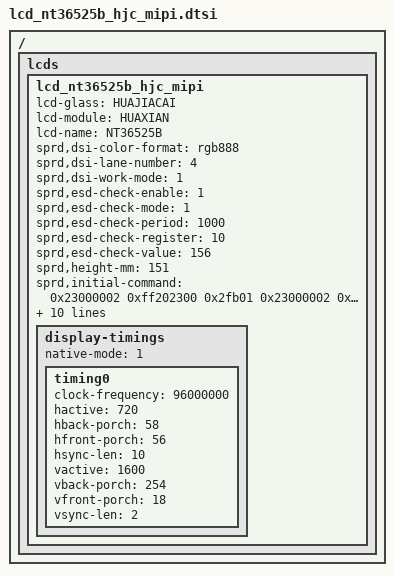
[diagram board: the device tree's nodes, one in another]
/ {
	fragment {
		target-path = "/";
		__overlay__ {
			lcds {
				lcd_nt36525b_hjc_mipi: lcd_nt36525b_hjc_mipi {
					lcd-glass = "HUAJIACAI";
					lcd-module = "HUAXIAN";
					lcd-name = "NT36525B";
					sprd,dsi-color-format = "rgb888";
					sprd,dsi-lane-number = <4>;
					sprd,dsi-work-mode = <1>;
					sprd,esd-check-enable = <1>;
					sprd,esd-check-mode = <1>;
					sprd,esd-check-period = <1000>;
					sprd,esd-check-register = <10>;
					sprd,esd-check-value = <156>;
					sprd,height-mm = <151>;
					sprd,initial-command = <
						0x23000002 0xff202300 0x2fb01 0x23000002 0x3542300 0x205b1 0x23000002 0x76e2300
						0x208cb 0x23000002 0xe872300 0x20f69 0x23000002 0x69a92300 0x28800 0x23000002 0x89582300
						0x28a58 0x23000002 0x8b582300 0x28c58 0x23000002 0x95d72300 0x296d7 0x23000002 0xff232300
						0x2fb01 0x23000002 0x12b42300 0x215e9 0x23000002 0x160b2300 0x2ff24 0x23000002 0xfb012300
						0x20005 0x23000002 0x1002300 0x2021f 0x23000002 0x31e2300 0x20420 0x23000002 0x5002300
						0x20600 0x23000002 0x7002300 0x20800 0x23000002 0x90f2300 0x20a0e 0x23000002 0xb002300
						0x20c00 0x23000002 0xd0d2300 0x20e0c 0x23000002 0xf042300 0x21000 0x23000002 0x11002300
						0x21200 0x23000002 0x13002300 0x21400 0x23000002 0x15002300 0x21605 0x23000002 0x17002300
						0x2181f 0x23000002 0x191e2300 0x21a20 0x23000002 0x1b002300 0x21c00 0x23000002 0x1d002300
						0x21e00 0x23000002 0x1f0f2300 0x2200e 0x23000002 0x21002300 0x22200 0x23000002 0x230d2300
						0x2240c 0x23000002 0x25042300 0x22600 0x23000002 0x27002300 0x22800 0x23000002 0x29002300
						0x22a00 0x23000002 0x2b002300 0x22f06 0x23000002 0x30302300 0x23330 0x23000002 0x34062300
						0x23774 0x23000002 0x3a982300 0x23ba6 0x23000002 0x3d522300 0x24d12 0x23000002 0x4e342300
						0x25143 0x23000002 0x52212300 0x25542 0x23000002 0x56342300 0x25a98 0x23000002 0x5ba62300
						0x25c00 0x23000002 0x5d002300 0x25e08 0x23000002 0x60802300 0x26190 0x23000002 0x64112300
						0x292b3 0x23000002 0x930a2300 0x2940e 0x23000002 0xab002300 0x2ad00 0x23000002 0xb0052300
						0x2b1af 0x23000002 0xff252300 0x2fb01 0x23000002 0xa822300 0x20b25 0x23000002 0xc012300
						0x21782 0x23000002 0x18062300 0x2190f 0x23000002 0xff262300 0x2fb01 0x23000002 0xa02300
						0x2ff27 0x23000002 0xfb012300 0x21300 0x23000002 0x15b42300 0x21f55 0x23000002 0x260f2300
						0x2c018 0x23000002 0xc1f22300 0x2c200 0x23000002 0xc3002300 0x2c4f2 0x23000002 0xc5002300
						0x2c600 0x23000002 0xffd02300 0x2fb01 0x23000002 0x5072300 0x209f0 0x23000002 0x28702300
						0x2ff10 0x23000002 0xfb012300 0x2ba03 0x23000002 0x35002300 0x2517f 0x23000002 0x53242396
						0x12923 0x32000111
					>;
					sprd,is_ic_nt36525b = <1>;
					sprd,nt36525b_is_hjc_flag = <1>;
					sprd,phy-bit-clock = <656640>;
					sprd,phy-escape-clock = <20000>;
					sprd,reset-on-sequence = <1 10 0 10 1 20>;
					sprd,sleep-in-command = [23 32 00 01 28 23 96 00 01 10];
					sprd,sleep-out-command = [23 96 00 01 11 23 32 00 01 29];
					sprd,width-mm = <68>;

					display-timings {
						native-mode = <1>;

						timing0: timing0 {
							clock-frequency = <96000000>;
							hactive = <720>;
							hback-porch = <58>;
							hfront-porch = <56>;
							hsync-len = <10>;
							vactive = <1600>;
							vback-porch = <254>;
							vfront-porch = <18>;
							vsync-len = <2>;
						};
					};
				};
			};
		};
	};
};

